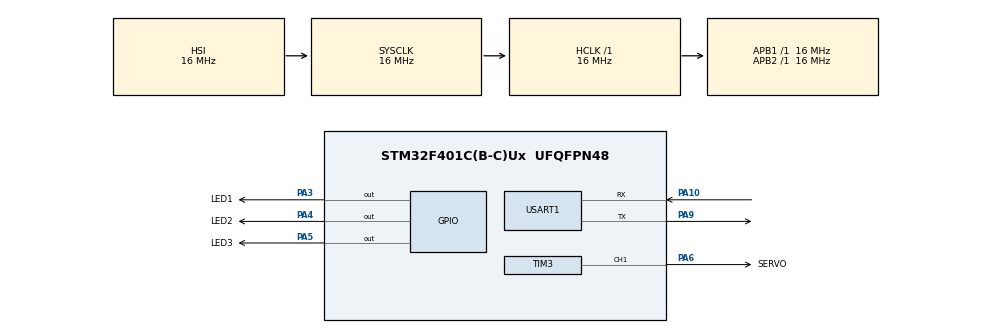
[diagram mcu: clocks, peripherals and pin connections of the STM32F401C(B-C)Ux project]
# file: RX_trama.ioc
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Dma.Request0=USART1_RX
Dma.USART1_RX.0.Direction=DMA_PERIPH_TO_MEMORY
Dma.USART1_RX.0.FIFOMode=DMA_FIFOMODE_DISABLE
Dma.USART1_RX.0.Instance=DMA2_Stream2
Dma.USART1_RX.0.MemDataAlignment=DMA_MDATAALIGN_BYTE
Dma.USART1_RX.0.MemInc=DMA_MINC_ENABLE
Dma.USART1_RX.0.Mode=DMA_NORMAL
Dma.USART1_RX.0.PeriphDataAlignment=DMA_PDATAALIGN_BYTE
Dma.USART1_RX.0.PeriphInc=DMA_PINC_DISABLE
Dma.USART1_RX.0.Priority=DMA_PRIORITY_LOW
Mcu.Family=STM32F4
Mcu.Name=STM32F401C(B-C)Ux
Mcu.Package=UFQFPN48
NVIC.DMA2_Stream2_IRQn=true\:0\:0\:false\:false\:true\:false\:true\:true
NVIC.PriorityGroup=NVIC_PRIORITYGROUP_4
NVIC.USART1_IRQn=true\:0\:0\:false\:false\:true\:true\:true\:true
PA10.Mode=Asynchronous
PA10.Signal=USART1_RX
PA3.GPIO_Label=LED1
PA3.Signal=GPIO_Output
PA4.GPIO_Label=LED2
PA4.Signal=GPIO_Output
PA5.GPIO_Label=LED3
PA5.Signal=GPIO_Output
PA6.GPIO_Label=SERVO
PA6.Signal=S_TIM3_CH1
PA9.Mode=Asynchronous
PA9.Signal=USART1_TX
ProjectManager.HeapSize=0x200
ProjectManager.StackSize=0x400
ProjectManager.TargetToolchain=CMake
RCC.AHBFreq_Value=16000000
RCC.APB1Freq_Value=16000000
RCC.APB2Freq_Value=16000000
RCC.CortexFreq_Value=16000000
RCC.HSE_VALUE=25000000
RCC.HSI_VALUE=16000000
RCC.LSE_VALUE=32768
RCC.SYSCLKFreq_VALUE=16000000
RCC.VCOOutputFreq_Value=192000000
SH.S_TIM3_CH1.0=TIM3_CH1,PWM Generation1 CH1
TIM3.AutoReloadPreload=TIM_AUTORELOAD_PRELOAD_ENABLE
TIM3.Channel-PWM\ Generation1\ CH1=TIM_CHANNEL_1
TIM3.Period=20000
TIM3.Prescaler=15
USART1.VirtualMode=VM_ASYNC
VP_TIM3_VS_ClockSourceINT.Mode=Internal
board=custom

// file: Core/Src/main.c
/* USER CODE BEGIN Header */
/**
  ******************************************************************************
  * @file           : main.c
  * @brief          : Main program body
  ******************************************************************************
  * @attention
  *
  * Copyright (c) 2026 STMicroelectronics.
  * All rights reserved.
  *
  * This software is licensed under terms that can be found in the LICENSE file
  * in the root directory of this software component.
  * If no LICENSE file comes with this software, it is provided AS-IS.
  *
  ******************************************************************************
  */
/* USER CODE END Header */
#include "main.h"

/* USER CODE BEGIN Includes */
#include "UARTRX.h"
#include "uart.h"

#include "MAP_.h"
#include "servos.h"

extern SERVOS SERVO1;
/* USER CODE END Includes */

TIM_HandleTypeDef htim3;

UART_HandleTypeDef huart1;
DMA_HandleTypeDef hdma_usart1_rx;

void SystemClock_Config(void);
static void MX_GPIO_Init(void);
static void MX_DMA_Init(void);
static void MX_TIM3_Init(void);
static void MX_USART1_UART_Init(void);
void procesa_rx(void);

int main(void)
{

  /* MCU Configuration--------------------------------------------------------*/

  /* Reset of all peripherals, Initializes the Flash interface and the Systick. */
  HAL_Init();

  /* Configure the system clock */
  SystemClock_Config();

  /* Initialize all configured peripherals */
  MX_GPIO_Init();
  MX_DMA_Init();
  MX_TIM3_Init();
  SERVO_init(&SERVO1);
  MX_USART1_UART_Init();
  /* USER CODE BEGIN 2 */
uartRX_it_idle_dma_init( &UARTRX1);
HAL_GPIO_WritePin(GPIOA, GPIO_PIN_3|GPIO_PIN_4|GPIO_PIN_5, GPIO_PIN_RESET);
SERVO_ANG(&SERVO1, 0.0f);   // centro
  /* USER CODE END 2 */

  /* Infinite loop */
  /* USER CODE BEGIN WHILE */
  while (1)
  {
    if (UARTRX1.flag_rx==1)// si hay algo ingresa
	  {
	     //uartx_write_text(&huart1, UARTRX1.trama_rx); //Transcribir lo que llego
	    procesa_rx(); //procedimeinto donde se procesan los datos
		  uartRX_DMA_Re_init(&UARTRX1); // y vuelvo a pedir más
	  }

    /* USER CODE END WHILE */

  }
}

void SystemClock_Config(void)
{
  RCC_OscInitTypeDef RCC_OscInitStruct = {0};
  RCC_ClkInitTypeDef RCC_ClkInitStruct = {0};

  /** Configure the main internal regulator output voltage
  */
  __HAL_RCC_PWR_CLK_ENABLE();
  __HAL_PWR_VOLTAGESCALING_CONFIG(PWR_REGULATOR_VOLTAGE_SCALE2);

  /** Initializes the RCC Oscillators according to the specified parameters
  * in the RCC_OscInitTypeDef structure.
  */
  RCC_OscInitStruct.OscillatorType = RCC_OSCILLATORTYPE_HSI;
  RCC_OscInitStruct.HSIState = RCC_HSI_ON;
  RCC_OscInitStruct.HSICalibrationValue = RCC_HSICALIBRATION_DEFAULT;
  RCC_OscInitStruct.PLL.PLLState = RCC_PLL_NONE;
  if (HAL_RCC_OscConfig(&RCC_OscInitStruct) != HAL_OK)
  {
    Error_Handler();
  }

  /** Initializes the CPU, AHB and APB buses clocks
  */
  RCC_ClkInitStruct.ClockType = RCC_CLOCKTYPE_HCLK|RCC_CLOCKTYPE_SYSCLK
                              |RCC_CLOCKTYPE_PCLK1|RCC_CLOCKTYPE_PCLK2;
  RCC_ClkInitStruct.SYSCLKSource = RCC_SYSCLKSOURCE_HSI;
  RCC_ClkInitStruct.AHBCLKDivider = RCC_SYSCLK_DIV1;
  RCC_ClkInitStruct.APB1CLKDivider = RCC_HCLK_DIV1;
  RCC_ClkInitStruct.APB2CLKDivider = RCC_HCLK_DIV1;

  if (HAL_RCC_ClockConfig(&RCC_ClkInitStruct, FLASH_LATENCY_0) != HAL_OK)
  {
    Error_Handler();
  }
}

static void MX_TIM3_Init(void)
{

  TIM_ClockConfigTypeDef sClockSourceConfig = {0};
  TIM_MasterConfigTypeDef sMasterConfig = {0};
  TIM_OC_InitTypeDef sConfigOC = {0};

  htim3.Instance = TIM3;
  htim3.Init.Prescaler = 15;
  htim3.Init.CounterMode = TIM_COUNTERMODE_UP;
  htim3.Init.Period = 20000;
  htim3.Init.ClockDivision = TIM_CLOCKDIVISION_DIV1;
  htim3.Init.AutoReloadPreload = TIM_AUTORELOAD_PRELOAD_ENABLE;
  if (HAL_TIM_Base_Init(&htim3) != HAL_OK)
  {
    Error_Handler();
  }
  sClockSourceConfig.ClockSource = TIM_CLOCKSOURCE_INTERNAL;
  if (HAL_TIM_ConfigClockSource(&htim3, &sClockSourceConfig) != HAL_OK)
  {
    Error_Handler();
  }
  if (HAL_TIM_PWM_Init(&htim3) != HAL_OK)
  {
    Error_Handler();
  }
  sMasterConfig.MasterOutputTrigger = TIM_TRGO_RESET;
  sMasterConfig.MasterSlaveMode = TIM_MASTERSLAVEMODE_DISABLE;
  if (HAL_TIMEx_MasterConfigSynchronization(&htim3, &sMasterConfig) != HAL_OK)
  {
    Error_Handler();
  }
  sConfigOC.OCMode = TIM_OCMODE_PWM1;
  sConfigOC.Pulse = 0;
  sConfigOC.OCPolarity = TIM_OCPOLARITY_HIGH;
  sConfigOC.OCFastMode = TIM_OCFAST_DISABLE;
  if (HAL_TIM_PWM_ConfigChannel(&htim3, &sConfigOC, TIM_CHANNEL_1) != HAL_OK)
  {
    Error_Handler();
  }
  HAL_TIM_MspPostInit(&htim3);

}

static void MX_USART1_UART_Init(void)
{

  huart1.Instance = USART1;
  huart1.Init.BaudRate = 115200;
  huart1.Init.WordLength = UART_WORDLENGTH_8B;
  huart1.Init.StopBits = UART_STOPBITS_1;
  huart1.Init.Parity = UART_PARITY_NONE;
  huart1.Init.Mode = UART_MODE_TX_RX;
  huart1.Init.HwFlowCtl = UART_HWCONTROL_NONE;
  huart1.Init.OverSampling = UART_OVERSAMPLING_16;
  if (HAL_UART_Init(&huart1) != HAL_OK)
  {
    Error_Handler();
  }

}

static void MX_DMA_Init(void)
{

  /* DMA controller clock enable */
  __HAL_RCC_DMA2_CLK_ENABLE();

  /* DMA interrupt init */
  /* DMA2_Stream2_IRQn interrupt configuration */
  HAL_NVIC_SetPriority(DMA2_Stream2_IRQn, 0, 0);
  HAL_NVIC_EnableIRQ(DMA2_Stream2_IRQn);

}

static void MX_GPIO_Init(void)
{
  GPIO_InitTypeDef GPIO_InitStruct = {0};

  /* GPIO Ports Clock Enable */
  __HAL_RCC_GPIOA_CLK_ENABLE();

  /*Configure GPIO pin Output Level */
  HAL_GPIO_WritePin(GPIOA, LED1_Pin|LED2_Pin|LED3_Pin, GPIO_PIN_RESET);

  /*Configure GPIO pins : LED1_Pin LED2_Pin LED3_Pin */
  GPIO_InitStruct.Pin = LED1_Pin|LED2_Pin|LED3_Pin;
  GPIO_InitStruct.Mode = GPIO_MODE_OUTPUT_PP;
  GPIO_InitStruct.Pull = GPIO_NOPULL;
  GPIO_InitStruct.Speed = GPIO_SPEED_FREQ_LOW;
  HAL_GPIO_Init(GPIOA, &GPIO_InitStruct);

}

void Error_Handler(void)
{
  __disable_irq();
  while (1)
  {
  }
}
